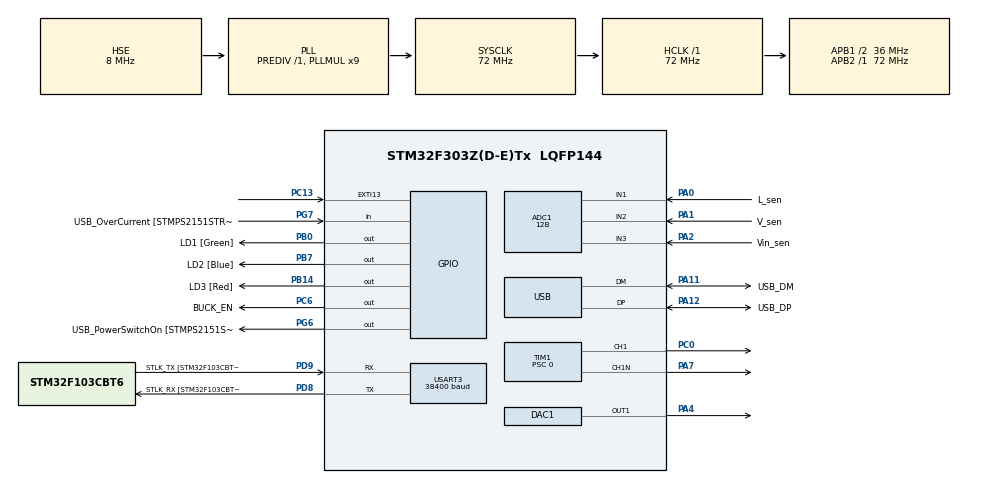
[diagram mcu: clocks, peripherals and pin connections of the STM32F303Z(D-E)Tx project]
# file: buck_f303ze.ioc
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# Reconstructed v0.0.2 buck development profile; not validated by CubeMX Generate Code.
# Requires independent PC6 gate-enable wiring; keep BUCK_BOARD_VERIFIED=0 until hardware verification.
ADC1.Channel-0\#ChannelRegularConversion=ADC_CHANNEL_1
ADC1.Channel-1\#ChannelRegularConversion=ADC_CHANNEL_2
ADC1.Channel-2\#ChannelRegularConversion=ADC_CHANNEL_3
ADC1.ClockPrescaler=ADC_CLOCK_ASYNC_DIV1
ADC1.ContinuousConvMode=DISABLE
ADC1.DMAContinuousRequests=ENABLE
ADC1.DataAlign=ADC_DATAALIGN_RIGHT
ADC1.DiscontinuousConvMode=DISABLE
ADC1.EOCSelection=ADC_EOC_SEQ_CONV
ADC1.ExternalTrigConv=ADC_EXTERNALTRIGCONV_T1_TRGO
ADC1.ExternalTrigConvEdge=ADC_EXTERNALTRIGCONVEDGE_RISING
ADC1.LowPowerAutoWait=DISABLE
ADC1.NbrOfConversion=3
ADC1.NbrOfConversionFlag=1
ADC1.Offset-0\#ChannelRegularConversion=0
ADC1.Offset-1\#ChannelRegularConversion=0
ADC1.Offset-2\#ChannelRegularConversion=0
ADC1.OffsetNumber-0\#ChannelRegularConversion=ADC_OFFSET_NONE
ADC1.OffsetNumber-1\#ChannelRegularConversion=ADC_OFFSET_NONE
ADC1.OffsetNumber-2\#ChannelRegularConversion=ADC_OFFSET_NONE
ADC1.Overrun=ADC_OVR_DATA_PRESERVED
ADC1.Rank-0\#ChannelRegularConversion=1
ADC1.Rank-1\#ChannelRegularConversion=2
ADC1.Rank-2\#ChannelRegularConversion=3
ADC1.Resolution=ADC_RESOLUTION_12B
ADC1.SamplingTime-0\#ChannelRegularConversion=ADC_SAMPLETIME_19CYCLES_5
ADC1.SamplingTime-1\#ChannelRegularConversion=ADC_SAMPLETIME_19CYCLES_5
ADC1.SamplingTime-2\#ChannelRegularConversion=ADC_SAMPLETIME_19CYCLES_5
ADC1.SamplingTimeOPAMP-0\#ChannelRegularConversion=ADC_SAMPLETIME_61CYCLES_5
ADC1.SamplingTimeOPAMP-1\#ChannelRegularConversion=ADC_SAMPLETIME_61CYCLES_5
ADC1.SamplingTimeOPAMP-2\#ChannelRegularConversion=ADC_SAMPLETIME_61CYCLES_5
ADC1.ScanConvMode=ADC_SCAN_ENABLE
ADC1.master=1
Dma.ADC1.0.Direction=DMA_PERIPH_TO_MEMORY
Dma.ADC1.0.Instance=DMA1_Channel1
Dma.ADC1.0.MemDataAlignment=DMA_MDATAALIGN_HALFWORD
Dma.ADC1.0.MemInc=DMA_MINC_ENABLE
Dma.ADC1.0.Mode=DMA_CIRCULAR
Dma.ADC1.0.PeriphDataAlignment=DMA_PDATAALIGN_HALFWORD
Dma.ADC1.0.PeriphInc=DMA_PINC_DISABLE
Dma.ADC1.0.Priority=DMA_PRIORITY_HIGH
Dma.Request0=ADC1
Mcu.Family=STM32F3
Mcu.Name=STM32F303Z(D-E)Tx
Mcu.Package=LQFP144
NVIC.ADC1_2_IRQn=true\:0\:0\:false\:false\:true\:true\:true\:true
NVIC.DMA1_Channel1_IRQn=true\:0\:0\:false\:false\:true\:true\:true\:true
NVIC.EXTI15_10_IRQn=true\:0\:0\:false\:false\:true\:true\:true\:true
NVIC.PriorityGroup=NVIC_PRIORITYGROUP_4
NVIC.TIM1_BRK_TIM15_IRQn=true\:0\:0\:false\:false\:true\:true\:true\:true
NVIC.TIM1_CC_IRQn=true\:0\:0\:false\:false\:true\:true\:true\:true
NVIC.TIM1_TRG_COM_TIM17_IRQn=true\:0\:0\:false\:false\:true\:true\:true\:true
NVIC.TIM1_UP_TIM16_IRQn=true\:0\:0\:false\:false\:true\:true\:true\:true
NVIC.USB_LP_CAN_RX0_IRQn=true\:2\:0\:false\:false\:true\:true\:true\:true
PA0.GPIO_Label=L_sen
PA0.Mode=IN1-Single-Ended
PA0.Signal=ADC1_IN1
PA1.GPIO_Label=V_sen
PA1.Mode=IN2-Single-Ended
PA1.Signal=ADC1_IN2
PA11.GPIO_Label=USB_DM
PA11.Mode=Device
PA11.Signal=USB_DM
PA12.GPIO_Label=USB_DP
PA12.Mode=Device
PA12.Signal=USB_DP
PA13.GPIO_Label=TMS
PA13.Mode=Serial_Wire
PA13.Signal=SYS_JTMS-SWDIO
PA14.GPIO_Label=TCK
PA14.Mode=Serial_Wire
PA14.Signal=SYS_JTCK-SWCLK
PA2.GPIO_Label=Vin_sen
PA2.Mode=IN3-Single-Ended
PA2.Signal=ADC1_IN3
PA4.Signal=COMP_DAC11_group
PA7.Mode=PWM Generation1 CH1 CH1N
PA7.Signal=TIM1_CH1N
PB0.GPIO_Label=LD1 [Green]
PB0.Signal=GPIO_Output
PB14.GPIO_Label=LD3 [Red]
PB14.Signal=GPIO_Output
PB3.GPIO_Label=SWO
PB3.Signal=SYS_JTDO-TRACESWO
PB7.GPIO_Label=LD2 [Blue]
PB7.Signal=GPIO_Output
PC0.Signal=S_TIM1_CH1
PC13.Signal=GPXTI13
PC14-OSC32_IN.Mode=LSE-External-Oscillator
PC14-OSC32_IN.Signal=RCC_OSC32_IN
PC15-OSC32_OUT.Mode=LSE-External-Oscillator
PC15-OSC32_OUT.Signal=RCC_OSC32_OUT
PC6.GPIO_Label=BUCK_EN
PC6.GPIO_ModeDefaultOutputPP=GPIO_MODE_OUTPUT_PP
PC6.GPIO_PuPd=GPIO_NOPULL
PC6.GPIO_Speed=GPIO_SPEED_FREQ_LOW
PC6.PinState=GPIO_PIN_RESET
PC6.Signal=GPIO_Output
PD8.GPIO_Label=STLK_RX [STM32F103CBT6_PA3]
PD8.Mode=Asynchronous
PD8.Signal=USART3_TX
PD9.GPIO_Label=STLK_TX [STM32F103CBT6_PA2]
PD9.Mode=Asynchronous
PD9.Signal=USART3_RX
PF0-OSC_IN.GPIO_Label=MCO [STM32F103CBT6_PA8]
PF0-OSC_IN.Mode=HSE-External-Clock-Source
PF0-OSC_IN.Signal=RCC_OSC_IN
PG6.GPIO_Label=USB_PowerSwitchOn [STMPS2151STR_EN]
PG6.Signal=GPIO_Output
PG7.GPIO_Label=USB_OverCurrent [STMPS2151STR_FAULT]
PG7.Signal=GPIO_Input
ProjectManager.HeapSize=0x200
ProjectManager.StackSize=0x400
ProjectManager.TargetToolchain=STM32CubeIDE
RCC.ADC12PRES=RCC_ADC12PLLCLK_DIV1
RCC.AHBFreq_Value=72000000
RCC.APB1CLKDivider=RCC_HCLK_DIV2
RCC.APB1Freq_Value=36000000
RCC.APB1TimFreq_Value=72000000
RCC.APB2Freq_Value=72000000
RCC.APB2TimFreq_Value=72000000
RCC.CortexFreq_Value=72000000
RCC.HCLKFreq_Value=72000000
RCC.HSE_VALUE=8000000
RCC.HSI_VALUE=8000000
RCC.PLLMUL=RCC_PLL_MUL9
RCC.PRESCALERUSB=RCC_USBCLKSOURCE_PLL_DIV1_5
RCC.SYSCLKFreq_VALUE=72000000
RCC.SYSCLKSourceVirtual=RCC_SYSCLKSOURCE_PLLCLK
RCC.USBFreq_Value=48000000
SH.COMP_DAC11_group.0=DAC1_OUT1,DAC_OUT1
SH.S_TIM1_CH1.0=TIM1_CH1,PWM Generation1 CH1 CH1N
TIM1.AutoReloadPreload=TIM_AUTORELOAD_PRELOAD_ENABLE
TIM1.AutomaticOutput=TIM_AUTOMATICOUTPUT_DISABLE
TIM1.Break2Filter=0
TIM1.Break2Polarity=TIM_BREAK2POLARITY_HIGH
TIM1.Break2State=TIM_BREAK2_DISABLE
TIM1.BreakFilter=0
TIM1.BreakPolarity=TIM_BREAKPOLARITY_HIGH
TIM1.BreakState=TIM_BREAK_DISABLE
TIM1.Channel-PWM\ Generation1\ CH1\ CH1N=TIM_CHANNEL_1
TIM1.Channel-PWM\ Generation4\ No\ Output=TIM_CHANNEL_4
TIM1.ClockDivision=TIM_CLOCKDIVISION_DIV1
TIM1.CounterMode=TIM_COUNTERMODE_UP
TIM1.DeadTime=22
TIM1.LockLevel=TIM_LOCKLEVEL_OFF
TIM1.OCFastMode_PWM-PWM\ Generation1\ CH1\ CH1N=TIM_OCFAST_DISABLE
TIM1.OCFastMode_PWM-PWM\ Generation4\ No\ Output=TIM_OCFAST_DISABLE
TIM1.OCIdleState_1=TIM_OCIDLESTATE_RESET
TIM1.OCMode_PWM-PWM\ Generation1\ CH1\ CH1N=TIM_OCMODE_PWM1
TIM1.OCMode_PWM-PWM\ Generation4\ No\ Output=TIM_OCMODE_PWM2
TIM1.OCNIdleState_1=TIM_OCNIDLESTATE_RESET
TIM1.OCNPolarity_1=TIM_OCNPOLARITY_HIGH
TIM1.OCPolarity_1=TIM_OCPOLARITY_HIGH
TIM1.OffStateIDLEMode=TIM_OSSI_ENABLE
TIM1.OffStateRunMode=TIM_OSSR_ENABLE
TIM1.Period=1439
TIM1.Prescaler=0
TIM1.Pulse-PWM\ Generation1\ CH1\ CH1N=0
TIM1.Pulse-PWM\ Generation4\ No\ Output=360
TIM1.RepetitionCounter=0
TIM1.TIM_MasterOutputTrigger=TIM_TRGO_OC4REF
TIM1.TIM_MasterOutputTrigger2=TIM_TRGO2_RESET
TIM1.TIM_MasterSlaveMode=TIM_MASTERSLAVEMODE_DISABLE
USART3.BaudRate=38400
USART3.VirtualMode-Asynchronous=VM_ASYNC
VP_RTC_VS_RTC_Activate.Mode=RTC_Enabled
VP_TIM1_VS_ClockSourceINT.Mode=Internal
VP_TIM1_VS_no_output4.Mode=PWM Generation4 No Output
board=NUCLEO-F303ZE

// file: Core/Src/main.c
/* USER CODE BEGIN Header */
/**
  ******************************************************************************
  * @file           : main.c
  * @brief          : Main program body
  ******************************************************************************
  * @attention
  *
  * Copyright (c) 2026 STMicroelectronics.
  * All rights reserved.
  *
  * This software is licensed under terms that can be found in the LICENSE file
  * in the root directory of this software component.
  * If no LICENSE file comes with this software, it is provided AS-IS.
  *
  ******************************************************************************
  */
/* USER CODE END Header */
#include "main.h"
/* USER CODE BEGIN Includes */
#include "buck_app.h" /* [직접 추가] 벅 제어 모듈 */
/* [0.0.2 수동 재구성본] 첨부한 CubeIDE 생성 파일의 형식/USER CODE 구역을 유지했습니다.
 * MX_*_Init/MSP/IRQ 설정은 buck_f303ze.ioc의 목표 프로필에 맞춰 수동 조정했습니다.
 * 실제 CubeMX Generate Code 결과라고 주장하지 않습니다. 재생성 후 설정을 비교하세요. */
/* USER CODE END Includes */

ADC_HandleTypeDef hadc1;
DMA_HandleTypeDef hdma_adc1;

DAC_HandleTypeDef hdac1;

RTC_HandleTypeDef hrtc;

TIM_HandleTypeDef htim1;

UART_HandleTypeDef huart3;

PCD_HandleTypeDef hpcd_USB_FS;

void SystemClock_Config(void);
static void MX_GPIO_Init(void);
static void MX_DMA_Init(void);
static void MX_RTC_Init(void);
static void MX_TIM1_Init(void);
static void MX_USART3_UART_Init(void);
static void MX_USB_PCD_Init(void);
static void MX_ADC1_Init(void);
static void MX_DAC1_Init(void);

int main(void)
{

  /* MCU Configuration--------------------------------------------------------*/

  /* Reset of all peripherals, Initializes the Flash interface and the Systick. */
  HAL_Init();

  /* Configure the system clock */
  SystemClock_Config();

  /* Initialize all configured peripherals */
  MX_GPIO_Init();
  MX_DMA_Init();
  MX_RTC_Init();
  MX_TIM1_Init();
  MX_USART3_UART_Init();
  MX_USB_PCD_Init();
  MX_ADC1_Init();
  MX_DAC1_Init();
  /* USER CODE BEGIN 2 */
  /* [직접 추가] 초기화 완료 후 ADC/DMA와 기동 순서는 이 모듈이 관리합니다.
   * HAL_TIM_PWM_Start()/PWMN_Start() 및 ADC 시작을 여기에 따로 추가하지 마세요.
   * BUCK_BOARD_VERIFIED=0은 유지합니다. 배선/센싱/보호 확인 전에는 기동 금지입니다. */
  Buck_Init();
/* USER CODE END 2 */

  /* Infinite loop */
  while (1)
  {

    /* USER CODE BEGIN 3 */
    /* [직접 추가] ADC 갱신 정지 감시. HAL_Delay/긴 대기를 넣지 마세요. */
    Buck_Poll();
  }
  /* USER CODE END 3 */
}

void SystemClock_Config(void)
{
  RCC_OscInitTypeDef RCC_OscInitStruct = {0};
  RCC_ClkInitTypeDef RCC_ClkInitStruct = {0};
  RCC_PeriphCLKInitTypeDef PeriphClkInit = {0};

  /** Initializes the RCC Oscillators according to the specified parameters
  * in the RCC_OscInitTypeDef structure.
  */
  RCC_OscInitStruct.OscillatorType = RCC_OSCILLATORTYPE_LSI|RCC_OSCILLATORTYPE_HSE;
  RCC_OscInitStruct.HSEState = RCC_HSE_BYPASS;
  RCC_OscInitStruct.HSIState = RCC_HSI_ON;
  RCC_OscInitStruct.LSIState = RCC_LSI_ON;
  RCC_OscInitStruct.PLL.PLLState = RCC_PLL_ON;
  RCC_OscInitStruct.PLL.PLLSource = RCC_PLLSOURCE_HSE;
  RCC_OscInitStruct.PLL.PLLMUL = RCC_PLL_MUL9;
  RCC_OscInitStruct.PLL.PREDIV = RCC_PREDIV_DIV1;
  if (HAL_RCC_OscConfig(&RCC_OscInitStruct) != HAL_OK)
  {
    Error_Handler();
  }

  /** Initializes the CPU, AHB and APB buses clocks
  */
  RCC_ClkInitStruct.ClockType = RCC_CLOCKTYPE_HCLK|RCC_CLOCKTYPE_SYSCLK
                              |RCC_CLOCKTYPE_PCLK1|RCC_CLOCKTYPE_PCLK2;
  RCC_ClkInitStruct.SYSCLKSource = RCC_SYSCLKSOURCE_PLLCLK;
  RCC_ClkInitStruct.AHBCLKDivider = RCC_SYSCLK_DIV1;
  RCC_ClkInitStruct.APB1CLKDivider = RCC_HCLK_DIV2;
  RCC_ClkInitStruct.APB2CLKDivider = RCC_HCLK_DIV1;

  if (HAL_RCC_ClockConfig(&RCC_ClkInitStruct, FLASH_LATENCY_2) != HAL_OK)
  {
    Error_Handler();
  }
  PeriphClkInit.PeriphClockSelection = RCC_PERIPHCLK_USB|RCC_PERIPHCLK_USART3
                              |RCC_PERIPHCLK_RTC|RCC_PERIPHCLK_TIM1
                              |RCC_PERIPHCLK_ADC12;
  PeriphClkInit.Usart3ClockSelection = RCC_USART3CLKSOURCE_PCLK1;
  PeriphClkInit.RTCClockSelection = RCC_RTCCLKSOURCE_LSI;
  PeriphClkInit.USBClockSelection = RCC_USBCLKSOURCE_PLL_DIV1_5;
  PeriphClkInit.Tim1ClockSelection = RCC_TIM1CLK_HCLK;
  PeriphClkInit.Adc12ClockSelection = RCC_ADC12PLLCLK_DIV1;
  if (HAL_RCCEx_PeriphCLKConfig(&PeriphClkInit) != HAL_OK)
  {
    Error_Handler();
  }
}

static void MX_ADC1_Init(void)
{

  ADC_MultiModeTypeDef multimode = {0};
  ADC_ChannelConfTypeDef sConfig = {0};

  /** Common config
  */
  hadc1.Instance = ADC1;
  hadc1.Init.ClockPrescaler = ADC_CLOCK_ASYNC_DIV1;
  hadc1.Init.Resolution = ADC_RESOLUTION_12B;
  hadc1.Init.ScanConvMode = ADC_SCAN_ENABLE;
  hadc1.Init.ContinuousConvMode = DISABLE;
  hadc1.Init.DiscontinuousConvMode = DISABLE;
  hadc1.Init.ExternalTrigConvEdge = ADC_EXTERNALTRIGCONVEDGE_RISING;
  hadc1.Init.ExternalTrigConv = ADC_EXTERNALTRIGCONV_T1_TRGO;
  hadc1.Init.DataAlign = ADC_DATAALIGN_RIGHT;
  hadc1.Init.NbrOfConversion = 3;
  hadc1.Init.DMAContinuousRequests = ENABLE;
  hadc1.Init.EOCSelection = ADC_EOC_SEQ_CONV;
  hadc1.Init.LowPowerAutoWait = DISABLE;
  hadc1.Init.Overrun = ADC_OVR_DATA_PRESERVED;
  if (HAL_ADC_Init(&hadc1) != HAL_OK)
  {
    Error_Handler();
  }

  /** Configure the ADC multi-mode
  */
  multimode.Mode = ADC_MODE_INDEPENDENT;
  if (HAL_ADCEx_MultiModeConfigChannel(&hadc1, &multimode) != HAL_OK)
  {
    Error_Handler();
  }

  /** Configure Regular Channel
  */
  sConfig.Channel = ADC_CHANNEL_1;
  sConfig.Rank = ADC_REGULAR_RANK_1;
  sConfig.SingleDiff = ADC_SINGLE_ENDED;
  sConfig.SamplingTime = ADC_SAMPLETIME_19CYCLES_5;
  sConfig.OffsetNumber = ADC_OFFSET_NONE;
  sConfig.Offset = 0;
  if (HAL_ADC_ConfigChannel(&hadc1, &sConfig) != HAL_OK)
  {
    Error_Handler();
  }
  sConfig.Channel = ADC_CHANNEL_2;
  sConfig.Rank = ADC_REGULAR_RANK_2;
  if (HAL_ADC_ConfigChannel(&hadc1, &sConfig) != HAL_OK)
  {
    Error_Handler();
  }
  sConfig.Channel = ADC_CHANNEL_3;
  sConfig.Rank = ADC_REGULAR_RANK_3;
  if (HAL_ADC_ConfigChannel(&hadc1, &sConfig) != HAL_OK)
  {
    Error_Handler();
  }

}

static void MX_DAC1_Init(void)
{

  DAC_ChannelConfTypeDef sConfig = {0};

  /** DAC Initialization
  */
  hdac1.Instance = DAC1;
  if (HAL_DAC_Init(&hdac1) != HAL_OK)
  {
    Error_Handler();
  }

  /** DAC channel OUT1 config
  */
  sConfig.DAC_Trigger = DAC_TRIGGER_NONE;
  sConfig.DAC_OutputBuffer = DAC_OUTPUTBUFFER_ENABLE;
  if (HAL_DAC_ConfigChannel(&hdac1, &sConfig, DAC_CHANNEL_1) != HAL_OK)
  {
    Error_Handler();
  }

}

static void MX_RTC_Init(void)
{

  /** Initialize RTC Only
  */
  hrtc.Instance = RTC;
  hrtc.Init.HourFormat = RTC_HOURFORMAT_24;
  hrtc.Init.AsynchPrediv = 127;
  hrtc.Init.SynchPrediv = 255;
  hrtc.Init.OutPut = RTC_OUTPUT_DISABLE;
  hrtc.Init.OutPutPolarity = RTC_OUTPUT_POLARITY_HIGH;
  hrtc.Init.OutPutType = RTC_OUTPUT_TYPE_OPENDRAIN;
  if (HAL_RTC_Init(&hrtc) != HAL_OK)
  {
    Error_Handler();
  }

}

static void MX_TIM1_Init(void)
{

  TIM_ClockConfigTypeDef sClockSourceConfig = {0};
  TIM_MasterConfigTypeDef sMasterConfig = {0};
  TIM_OC_InitTypeDef sConfigOC = {0};
  TIM_BreakDeadTimeConfigTypeDef sBreakDeadTimeConfig = {0};

  htim1.Instance = TIM1;
  htim1.Init.Prescaler = 0;
  htim1.Init.CounterMode = TIM_COUNTERMODE_UP;
  htim1.Init.Period = 1439;
  htim1.Init.ClockDivision = TIM_CLOCKDIVISION_DIV1;
  htim1.Init.RepetitionCounter = 0;
  htim1.Init.AutoReloadPreload = TIM_AUTORELOAD_PRELOAD_ENABLE;
  if (HAL_TIM_Base_Init(&htim1) != HAL_OK)
  {
    Error_Handler();
  }
  sClockSourceConfig.ClockSource = TIM_CLOCKSOURCE_INTERNAL;
  if (HAL_TIM_ConfigClockSource(&htim1, &sClockSourceConfig) != HAL_OK)
  {
    Error_Handler();
  }
  if (HAL_TIM_PWM_Init(&htim1) != HAL_OK)
  {
    Error_Handler();
  }
  sMasterConfig.MasterOutputTrigger = TIM_TRGO_OC4REF;
  sMasterConfig.MasterOutputTrigger2 = TIM_TRGO2_RESET;
  sMasterConfig.MasterSlaveMode = TIM_MASTERSLAVEMODE_DISABLE;
  if (HAL_TIMEx_MasterConfigSynchronization(&htim1, &sMasterConfig) != HAL_OK)
  {
    Error_Handler();
  }
  sConfigOC.OCMode = TIM_OCMODE_PWM1;
  sConfigOC.Pulse = 0;
  sConfigOC.OCPolarity = TIM_OCPOLARITY_HIGH;
  sConfigOC.OCNPolarity = TIM_OCNPOLARITY_HIGH;
  sConfigOC.OCFastMode = TIM_OCFAST_DISABLE;
  sConfigOC.OCIdleState = TIM_OCIDLESTATE_RESET;
  sConfigOC.OCNIdleState = TIM_OCNIDLESTATE_RESET;
  if (HAL_TIM_PWM_ConfigChannel(&htim1, &sConfigOC, TIM_CHANNEL_1) != HAL_OK)
  {
    Error_Handler();
  }
  sConfigOC.OCMode = TIM_OCMODE_PWM2;
  sConfigOC.Pulse = 360;
  if (HAL_TIM_PWM_ConfigChannel(&htim1, &sConfigOC, TIM_CHANNEL_4) != HAL_OK)
  {
    Error_Handler();
  }
  sBreakDeadTimeConfig.OffStateRunMode = TIM_OSSR_ENABLE;
  sBreakDeadTimeConfig.OffStateIDLEMode = TIM_OSSI_ENABLE;
  sBreakDeadTimeConfig.LockLevel = TIM_LOCKLEVEL_OFF;
  sBreakDeadTimeConfig.DeadTime = 22;
  sBreakDeadTimeConfig.BreakState = TIM_BREAK_DISABLE;
  sBreakDeadTimeConfig.BreakPolarity = TIM_BREAKPOLARITY_HIGH;
  sBreakDeadTimeConfig.BreakFilter = 0;
  sBreakDeadTimeConfig.Break2State = TIM_BREAK2_DISABLE;
  sBreakDeadTimeConfig.Break2Polarity = TIM_BREAK2POLARITY_HIGH;
  sBreakDeadTimeConfig.Break2Filter = 0;
  sBreakDeadTimeConfig.AutomaticOutput = TIM_AUTOMATICOUTPUT_DISABLE;
  if (HAL_TIMEx_ConfigBreakDeadTime(&htim1, &sBreakDeadTimeConfig) != HAL_OK)
  {
    Error_Handler();
  }
  HAL_TIM_MspPostInit(&htim1);

}

static void MX_USART3_UART_Init(void)
{

  huart3.Instance = USART3;
  huart3.Init.BaudRate = 38400;
  huart3.Init.WordLength = UART_WORDLENGTH_8B;
  huart3.Init.StopBits = UART_STOPBITS_1;
  huart3.Init.Parity = UART_PARITY_NONE;
  huart3.Init.Mode = UART_MODE_TX_RX;
  huart3.Init.HwFlowCtl = UART_HWCONTROL_NONE;
  huart3.Init.OverSampling = UART_OVERSAMPLING_16;
  huart3.Init.OneBitSampling = UART_ONE_BIT_SAMPLE_DISABLE;
  huart3.AdvancedInit.AdvFeatureInit = UART_ADVFEATURE_NO_INIT;
  if (HAL_UART_Init(&huart3) != HAL_OK)
  {
    Error_Handler();
  }

}

static void MX_USB_PCD_Init(void)
{

  hpcd_USB_FS.Instance = USB;
  hpcd_USB_FS.Init.dev_endpoints = 8;
  hpcd_USB_FS.Init.speed = PCD_SPEED_FULL;
  hpcd_USB_FS.Init.phy_itface = PCD_PHY_EMBEDDED;
  hpcd_USB_FS.Init.low_power_enable = DISABLE;
  hpcd_USB_FS.Init.lpm_enable = DISABLE;
  hpcd_USB_FS.Init.battery_charging_enable = DISABLE;
  if (HAL_PCD_Init(&hpcd_USB_FS) != HAL_OK)
  {
    Error_Handler();
  }

}

static void MX_DMA_Init(void)
{
  __HAL_RCC_DMA1_CLK_ENABLE();
  HAL_NVIC_SetPriority(DMA1_Channel1_IRQn, 0, 0);
  HAL_NVIC_EnableIRQ(DMA1_Channel1_IRQn);
}

static void MX_GPIO_Init(void)
{
  GPIO_InitTypeDef GPIO_InitStruct = {0};

  /* GPIO Ports Clock Enable */
  __HAL_RCC_GPIOC_CLK_ENABLE();
  __HAL_RCC_GPIOF_CLK_ENABLE();
  __HAL_RCC_GPIOA_CLK_ENABLE();
  __HAL_RCC_GPIOB_CLK_ENABLE();
  __HAL_RCC_GPIOD_CLK_ENABLE();
  __HAL_RCC_GPIOG_CLK_ENABLE();

  /*Configure GPIO pin Output Level */
  HAL_GPIO_WritePin(BUCK_EN_GPIO_Port, BUCK_EN_Pin, GPIO_PIN_RESET);

  /*Configure GPIO pin Output Level */
  HAL_GPIO_WritePin(GPIOB, LD1_Pin|LD3_Pin|LD2_Pin, GPIO_PIN_RESET);

  /*Configure GPIO pin Output Level */
  HAL_GPIO_WritePin(USB_PowerSwitchOn_GPIO_Port, USB_PowerSwitchOn_Pin, GPIO_PIN_RESET);

  /*Configure GPIO pin : BUCK_EN_Pin */
  GPIO_InitStruct.Pin = BUCK_EN_Pin;
  GPIO_InitStruct.Mode = GPIO_MODE_OUTPUT_PP;
  GPIO_InitStruct.Pull = GPIO_NOPULL;
  GPIO_InitStruct.Speed = GPIO_SPEED_FREQ_LOW;
  HAL_GPIO_Init(BUCK_EN_GPIO_Port, &GPIO_InitStruct);

  /*Configure GPIO pin : PC13 */
  GPIO_InitStruct.Pin = GPIO_PIN_13;
  GPIO_InitStruct.Mode = GPIO_MODE_IT_RISING;
  GPIO_InitStruct.Pull = GPIO_NOPULL;
  HAL_GPIO_Init(GPIOC, &GPIO_InitStruct);

  /*Configure GPIO pins : LD1_Pin LD3_Pin LD2_Pin */
  GPIO_InitStruct.Pin = LD1_Pin|LD3_Pin|LD2_Pin;
  GPIO_InitStruct.Mode = GPIO_MODE_OUTPUT_PP;
  GPIO_InitStruct.Pull = GPIO_NOPULL;
  GPIO_InitStruct.Speed = GPIO_SPEED_FREQ_LOW;
  HAL_GPIO_Init(GPIOB, &GPIO_InitStruct);

  /*Configure GPIO pin : USB_PowerSwitchOn_Pin */
  GPIO_InitStruct.Pin = USB_PowerSwitchOn_Pin;
  GPIO_InitStruct.Mode = GPIO_MODE_OUTPUT_PP;
  GPIO_InitStruct.Pull = GPIO_NOPULL;
  GPIO_InitStruct.Speed = GPIO_SPEED_FREQ_LOW;
  HAL_GPIO_Init(USB_PowerSwitchOn_GPIO_Port, &GPIO_InitStruct);

  /*Configure GPIO pin : USB_OverCurrent_Pin */
  GPIO_InitStruct.Pin = USB_OverCurrent_Pin;
  GPIO_InitStruct.Mode = GPIO_MODE_INPUT;
  GPIO_InitStruct.Pull = GPIO_NOPULL;
  HAL_GPIO_Init(USB_OverCurrent_GPIO_Port, &GPIO_InitStruct);

  /* EXTI interrupt init*/
  HAL_NVIC_SetPriority(EXTI15_10_IRQn, 0, 0);
  HAL_NVIC_EnableIRQ(EXTI15_10_IRQn);

}

/* USER CODE BEGIN 4 */
/* [직접 추가] NUCLEO 파란 버튼은 시작 버튼이 아니라 정지 요청입니다.
 * ADC 콜백은 buck_app.c에 있으므로 이 파일에 중복 정의하지 않습니다. */
void HAL_GPIO_EXTI_Callback(uint16_t GPIO_Pin)
{
  if (GPIO_Pin == GPIO_PIN_13)
  {
    uint32_t irq_state = __get_PRIMASK();
    __disable_irq();
    buck_arm_request = 2u;
    Buck_EmergencyOff();
    __set_PRIMASK(irq_state);
  }
}
/* USER CODE END 4 */

void Error_Handler(void)
{
  /* USER CODE BEGIN Error_Handler_Debug */
  __disable_irq();
  /* [직접 추가] 오류 정지 루프에 들어가기 전에 EN LOW / MOE OFF */
  Buck_EmergencyOff();
  while (1)
  {
  }
/* USER CODE END Error_Handler_Debug */
}
